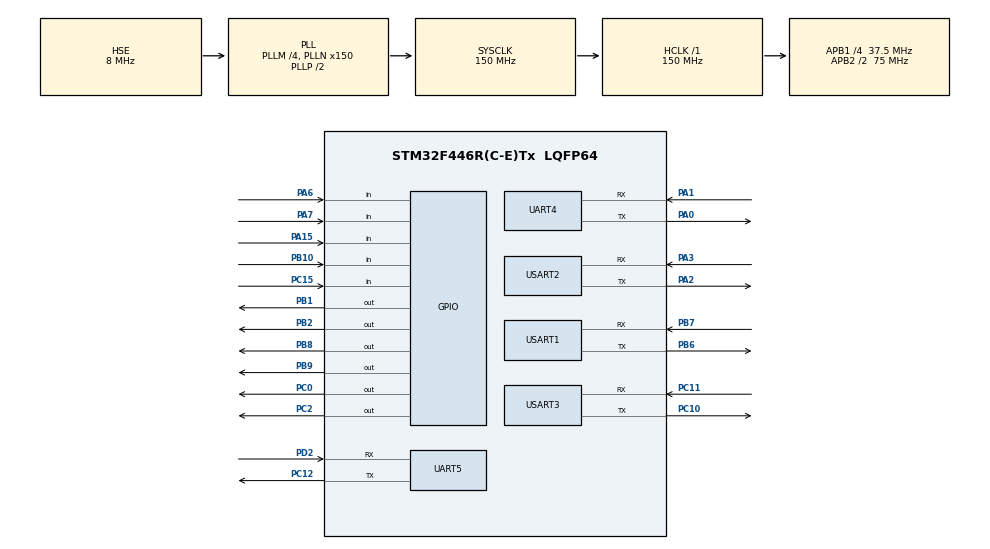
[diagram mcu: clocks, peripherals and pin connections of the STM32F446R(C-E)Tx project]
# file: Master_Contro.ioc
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Mcu.Family=STM32F4
Mcu.Name=STM32F446R(C-E)Tx
Mcu.Package=LQFP64
NVIC.PriorityGroup=NVIC_PRIORITYGROUP_4
NVIC.TIM1_UP_TIM10_IRQn=true\:0\:0\:false\:false\:true\:true\:true\:true
NVIC.UART4_IRQn=true\:0\:0\:false\:false\:true\:true\:true\:true
NVIC.UART5_IRQn=true\:0\:0\:false\:false\:true\:true\:true\:true
NVIC.USART1_IRQn=true\:0\:0\:false\:false\:true\:true\:true\:true
NVIC.USART2_IRQn=true\:0\:0\:false\:false\:true\:true\:true\:true
NVIC.USART3_IRQn=true\:0\:0\:false\:false\:true\:true\:true\:true
PA0-WKUP.Mode=Asynchronous
PA0-WKUP.Signal=UART4_TX
PA1.Mode=Asynchronous
PA1.Signal=UART4_RX
PA13.Mode=Serial_Wire
PA13.Signal=SYS_JTMS-SWDIO
PA14.Mode=Serial_Wire
PA14.Signal=SYS_JTCK-SWCLK
PA15.Signal=GPIO_Input
PA2.Mode=Asynchronous
PA2.Signal=USART2_TX
PA3.Mode=Asynchronous
PA3.Signal=USART2_RX
PA6.Signal=GPIO_Input
PA7.Signal=GPIO_Input
PB1.Signal=GPIO_Output
PB10.Signal=GPIO_Input
PB2.Signal=GPIO_Output
PB6.Mode=Asynchronous
PB6.Signal=USART1_TX
PB7.Mode=Asynchronous
PB7.Signal=USART1_RX
PB8.Signal=GPIO_Output
PB9.Signal=GPIO_Output
PC0.Signal=GPIO_Output
PC10.Mode=Asynchronous
PC10.Signal=USART3_TX
PC11.Mode=Asynchronous
PC11.Signal=USART3_RX
PC12.Mode=Asynchronous
PC12.Signal=UART5_TX
PC15-OSC32_OUT.Signal=GPIO_Input
PC2.Signal=GPIO_Output
PD2.Mode=Asynchronous
PD2.Signal=UART5_RX
PH0-OSC_IN.Mode=HSE-External-Oscillator
PH0-OSC_IN.Signal=RCC_OSC_IN
PH1-OSC_OUT.Mode=HSE-External-Oscillator
PH1-OSC_OUT.Signal=RCC_OSC_OUT
ProjectManager.HeapSize=0x200
ProjectManager.StackSize=0x400
ProjectManager.TargetToolchain=MDK-ARM V5.32
RCC.AHBFreq_Value=150000000
RCC.APB1CLKDivider=RCC_HCLK_DIV4
RCC.APB1Freq_Value=37500000
RCC.APB1TimFreq_Value=75000000
RCC.APB2CLKDivider=RCC_HCLK_DIV2
RCC.APB2Freq_Value=75000000
RCC.APB2TimFreq_Value=150000000
RCC.CortexFreq_Value=150000000
RCC.HCLKFreq_Value=150000000
RCC.HSE_VALUE=8000000
RCC.PLLM=4
RCC.PLLN=150
RCC.PLLSourceVirtual=RCC_PLLSOURCE_HSE
RCC.SYSCLKFreq_VALUE=150000000
RCC.SYSCLKSource=RCC_SYSCLKSOURCE_PLLCLK
RCC.USBFreq_Value=150000000
RCC.VCOOutputFreq_Value=300000000
TIM10.Period=2400
UART4.VirtualMode=Asynchronous
UART5.VirtualMode=Asynchronous
USART1.VirtualMode=VM_ASYNC
USART2.VirtualMode=VM_ASYNC
USART3.VirtualMode=VM_ASYNC
VP_TIM10_VS_ClockSourceINT.Mode=Enable_Timer
board=custom

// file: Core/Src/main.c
/* USER CODE BEGIN Header */
/**
  ******************************************************************************
  * @file           : main.c
  * @brief          : Main program body
  ******************************************************************************
  * @attention
  *
  * Copyright (c) 2025 STMicroelectronics.
  * All rights reserved.
  *
  * This software is licensed under terms that can be found in the LICENSE file
  * in the root directory of this software component.
  * If no LICENSE file comes with this software, it is provided AS-IS.
  *
  ******************************************************************************
  */
/* USER CODE END Header */
#include "main.h"

/* USER CODE BEGIN Includes */
#include "app_comm.h"
#include "task.h"
/* USER CODE END Includes */

TIM_HandleTypeDef htim10;

UART_HandleTypeDef huart4;
UART_HandleTypeDef huart5;
UART_HandleTypeDef huart1;
UART_HandleTypeDef huart2;
UART_HandleTypeDef huart3;

void SystemClock_Config(void);
static void MX_GPIO_Init(void);
static void MX_UART4_Init(void);
static void MX_UART5_Init(void);
static void MX_USART1_UART_Init(void);
static void MX_USART2_UART_Init(void);
static void MX_USART3_UART_Init(void);
static void MX_TIM10_Init(void);

int main(void)
{

  /* MCU Configuration--------------------------------------------------------*/

  /* Reset of all peripherals, Initializes the Flash interface and the Systick. */
  HAL_Init();

  /* Configure the system clock */
  SystemClock_Config();

  /* Initialize all configured peripherals */
  MX_GPIO_Init();
  MX_UART4_Init();
  MX_UART5_Init();
  MX_USART1_UART_Init();
  MX_USART2_UART_Init();
  MX_USART3_UART_Init();
  MX_TIM10_Init();

  /* Infinite loop */
  while (1)
  {

    /* USER CODE BEGIN 3 */
		static uint32_t last_time=0;
		if(HAL_GetTick() - last_time >=10)
		{
			last_time = HAL_GetTick();

			TrigProcess();

			DoorProcess();

			XrayioProcess();

			DeviceledProcess();

			CmdProcess();

			UartProcess();

			PhotoelectricSwitchProcess();

			FanProcess();
		}
  }
  /* USER CODE END 3 */
}

void SystemClock_Config(void)
{
  RCC_OscInitTypeDef RCC_OscInitStruct = {0};
  RCC_ClkInitTypeDef RCC_ClkInitStruct = {0};

  /** Configure the main internal regulator output voltage
  */
  __HAL_RCC_PWR_CLK_ENABLE();
  __HAL_PWR_VOLTAGESCALING_CONFIG(PWR_REGULATOR_VOLTAGE_SCALE1);

  /** Initializes the RCC Oscillators according to the specified parameters
  * in the RCC_OscInitTypeDef structure.
  */
  RCC_OscInitStruct.OscillatorType = RCC_OSCILLATORTYPE_HSE;
  RCC_OscInitStruct.HSEState = RCC_HSE_ON;
  RCC_OscInitStruct.PLL.PLLState = RCC_PLL_ON;
  RCC_OscInitStruct.PLL.PLLSource = RCC_PLLSOURCE_HSE;
  RCC_OscInitStruct.PLL.PLLM = 4;
  RCC_OscInitStruct.PLL.PLLN = 150;
  RCC_OscInitStruct.PLL.PLLP = RCC_PLLP_DIV2;
  RCC_OscInitStruct.PLL.PLLQ = 2;
  RCC_OscInitStruct.PLL.PLLR = 2;
  if (HAL_RCC_OscConfig(&RCC_OscInitStruct) != HAL_OK)
  {
    Error_Handler();
  }

  /** Initializes the CPU, AHB and APB buses clocks
  */
  RCC_ClkInitStruct.ClockType = RCC_CLOCKTYPE_HCLK|RCC_CLOCKTYPE_SYSCLK
                              |RCC_CLOCKTYPE_PCLK1|RCC_CLOCKTYPE_PCLK2;
  RCC_ClkInitStruct.SYSCLKSource = RCC_SYSCLKSOURCE_PLLCLK;
  RCC_ClkInitStruct.AHBCLKDivider = RCC_SYSCLK_DIV1;
  RCC_ClkInitStruct.APB1CLKDivider = RCC_HCLK_DIV4;
  RCC_ClkInitStruct.APB2CLKDivider = RCC_HCLK_DIV2;

  if (HAL_RCC_ClockConfig(&RCC_ClkInitStruct, FLASH_LATENCY_4) != HAL_OK)
  {
    Error_Handler();
  }
}

static void MX_TIM10_Init(void)
{

  htim10.Instance = TIM10;
  htim10.Init.Prescaler = 0;
  htim10.Init.CounterMode = TIM_COUNTERMODE_UP;
  htim10.Init.Period = 2400;
  htim10.Init.ClockDivision = TIM_CLOCKDIVISION_DIV1;
  htim10.Init.AutoReloadPreload = TIM_AUTORELOAD_PRELOAD_DISABLE;
  if (HAL_TIM_Base_Init(&htim10) != HAL_OK)
  {
    Error_Handler();
  }

}

static void MX_UART4_Init(void)
{

  huart4.Instance = UART4;
  huart4.Init.BaudRate = 115200;
  huart4.Init.WordLength = UART_WORDLENGTH_8B;
  huart4.Init.StopBits = UART_STOPBITS_1;
  huart4.Init.Parity = UART_PARITY_NONE;
  huart4.Init.Mode = UART_MODE_TX_RX;
  huart4.Init.HwFlowCtl = UART_HWCONTROL_NONE;
  huart4.Init.OverSampling = UART_OVERSAMPLING_16;
  if (HAL_UART_Init(&huart4) != HAL_OK)
  {
    Error_Handler();
  }

}

static void MX_UART5_Init(void)
{

  huart5.Instance = UART5;
  huart5.Init.BaudRate = 115200;
  huart5.Init.WordLength = UART_WORDLENGTH_8B;
  huart5.Init.StopBits = UART_STOPBITS_1;
  huart5.Init.Parity = UART_PARITY_NONE;
  huart5.Init.Mode = UART_MODE_TX_RX;
  huart5.Init.HwFlowCtl = UART_HWCONTROL_NONE;
  huart5.Init.OverSampling = UART_OVERSAMPLING_16;
  if (HAL_UART_Init(&huart5) != HAL_OK)
  {
    Error_Handler();
  }

}

static void MX_USART1_UART_Init(void)
{

  huart1.Instance = USART1;
  huart1.Init.BaudRate = 115200;
  huart1.Init.WordLength = UART_WORDLENGTH_8B;
  huart1.Init.StopBits = UART_STOPBITS_1;
  huart1.Init.Parity = UART_PARITY_NONE;
  huart1.Init.Mode = UART_MODE_TX_RX;
  huart1.Init.HwFlowCtl = UART_HWCONTROL_NONE;
  huart1.Init.OverSampling = UART_OVERSAMPLING_16;
  if (HAL_UART_Init(&huart1) != HAL_OK)
  {
    Error_Handler();
  }

}

static void MX_USART2_UART_Init(void)
{

  huart2.Instance = USART2;
  huart2.Init.BaudRate = 115200;
  huart2.Init.WordLength = UART_WORDLENGTH_8B;
  huart2.Init.StopBits = UART_STOPBITS_1;
  huart2.Init.Parity = UART_PARITY_NONE;
  huart2.Init.Mode = UART_MODE_TX_RX;
  huart2.Init.HwFlowCtl = UART_HWCONTROL_NONE;
  huart2.Init.OverSampling = UART_OVERSAMPLING_16;
  if (HAL_UART_Init(&huart2) != HAL_OK)
  {
    Error_Handler();
  }

}

static void MX_USART3_UART_Init(void)
{

  huart3.Instance = USART3;
  huart3.Init.BaudRate = 115200;
  huart3.Init.WordLength = UART_WORDLENGTH_8B;
  huart3.Init.StopBits = UART_STOPBITS_1;
  huart3.Init.Parity = UART_PARITY_NONE;
  huart3.Init.Mode = UART_MODE_TX_RX;
  huart3.Init.HwFlowCtl = UART_HWCONTROL_NONE;
  huart3.Init.OverSampling = UART_OVERSAMPLING_16;
  if (HAL_UART_Init(&huart3) != HAL_OK)
  {
    Error_Handler();
  }

}

static void MX_GPIO_Init(void)
{
  GPIO_InitTypeDef GPIO_InitStruct = {0};

  /* GPIO Ports Clock Enable */
  __HAL_RCC_GPIOC_CLK_ENABLE();
  __HAL_RCC_GPIOH_CLK_ENABLE();
  __HAL_RCC_GPIOA_CLK_ENABLE();
  __HAL_RCC_GPIOB_CLK_ENABLE();
  __HAL_RCC_GPIOD_CLK_ENABLE();

  /*Configure GPIO pin Output Level */
  HAL_GPIO_WritePin(GPIOC, GPIO_PIN_0|GPIO_PIN_2, GPIO_PIN_RESET);

  /*Configure GPIO pin Output Level */
  HAL_GPIO_WritePin(GPIOB, GPIO_PIN_1|GPIO_PIN_2|GPIO_PIN_8|GPIO_PIN_9, GPIO_PIN_RESET);

  /*Configure GPIO pin : PC15 */
  GPIO_InitStruct.Pin = GPIO_PIN_15;
  GPIO_InitStruct.Mode = GPIO_MODE_INPUT;
  GPIO_InitStruct.Pull = GPIO_NOPULL;
  HAL_GPIO_Init(GPIOC, &GPIO_InitStruct);

  /*Configure GPIO pins : PC0 PC2 */
  GPIO_InitStruct.Pin = GPIO_PIN_0|GPIO_PIN_2;
  GPIO_InitStruct.Mode = GPIO_MODE_OUTPUT_PP;
  GPIO_InitStruct.Pull = GPIO_NOPULL;
  GPIO_InitStruct.Speed = GPIO_SPEED_FREQ_LOW;
  HAL_GPIO_Init(GPIOC, &GPIO_InitStruct);

  /*Configure GPIO pins : PA6 PA7 PA15 */
  GPIO_InitStruct.Pin = GPIO_PIN_6|GPIO_PIN_7|GPIO_PIN_15;
  GPIO_InitStruct.Mode = GPIO_MODE_INPUT;
  GPIO_InitStruct.Pull = GPIO_NOPULL;
  HAL_GPIO_Init(GPIOA, &GPIO_InitStruct);

  /*Configure GPIO pins : PB1 PB2 PB8 PB9 */
  GPIO_InitStruct.Pin = GPIO_PIN_1|GPIO_PIN_2|GPIO_PIN_8|GPIO_PIN_9;
  GPIO_InitStruct.Mode = GPIO_MODE_OUTPUT_PP;
  GPIO_InitStruct.Pull = GPIO_NOPULL;
  GPIO_InitStruct.Speed = GPIO_SPEED_FREQ_LOW;
  HAL_GPIO_Init(GPIOB, &GPIO_InitStruct);

  /*Configure GPIO pin : PB10 */
  GPIO_InitStruct.Pin = GPIO_PIN_10;
  GPIO_InitStruct.Mode = GPIO_MODE_INPUT;
  GPIO_InitStruct.Pull = GPIO_NOPULL;
  HAL_GPIO_Init(GPIOB, &GPIO_InitStruct);

}

void Error_Handler(void)
{
  __disable_irq();
  while (1)
  {
  }
}
